# N32H488 register map
Vendor: Nationstech Ltd.; File version: 1.0
Registers are 32-bit, read-write, reset 0x0 unless marked. A register's access mark holds for its fields unless they carry their own. Offsets are from the block's base; [hi:lo] are bit positions; {n}, {i} and the like mark numbered series; 'fields as' and 'values as' point back to an identical list.

## SHRTIM_Master — Super high resolution timer: Master Timers
Base 0x40030000
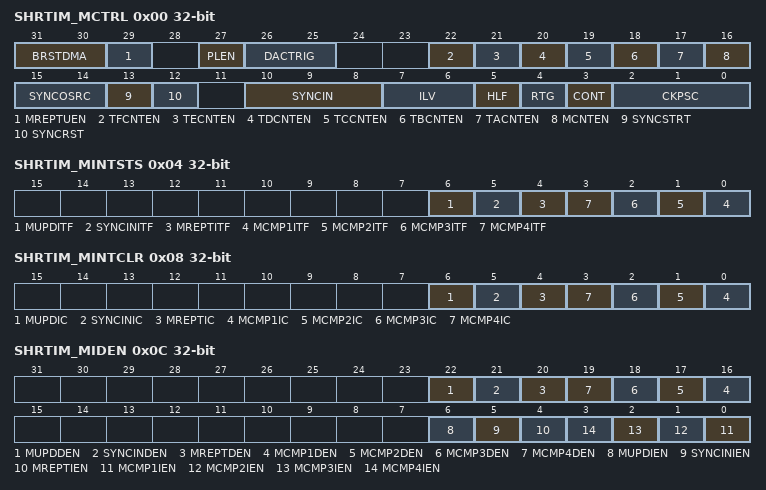
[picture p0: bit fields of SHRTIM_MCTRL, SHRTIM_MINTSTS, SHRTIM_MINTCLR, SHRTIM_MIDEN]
0x00 SHRTIM_MCTRL — SHRTIM configuration register for master timer
  [31:30] BRSTDMA, [29] MREPTUEN, [27] PLEN, [26:25] DACTRIG, [22] TFCNTEN, [21] TECNTEN, [20] TDCNTEN, [19] TCCNTEN, [18] TBCNTEN, [17] TACNTEN, [16] MCNTEN, [15:14] SYNCOSRC, [13] SYNCSTRT, [12] SYNCRST, [10:8] SYNCIN, [7:6] ILV, [5] HLF, [4] RTG, [3] CONT, [2:0] CKPSC
0x04 SHRTIM_MINTSTS ro — SHRTIM status register for master timer interrupt
  [6] MUPDITF, [5] SYNCINITF, [4] MREPTITF, [n-1] MCMP{n}ITF (n=1..4)
0x08 SHRTIM_MINTCLR wo — SHRTIM master timer interrupt clear register
  [6] MUPDIC, [5] SYNCINIC, [4] MREPTIC, [n-1] MCMP{n}IC (n=1..4)
0x0C SHRTIM_MIDEN — SHRTIM master timer interrupt and DMA request enable register
  [22] MUPDDEN, [21] SYNCINDEN, [20] MREPTDEN, [n+15] MCMP{n}DEN (n=1..4), [6] MUPDIEN, [5] SYNCINIEN, [4] MREPTIEN, [n-1] MCMP{n}IEN (n=1..4)
0x10 SHRTIM_MCNT — SHRTIM master timer counter register
  [15:0] MCOUNT
0x14 SHRTIM_MPRD reset 0xFFDF — SHRTIM master timer period register
  [15:0] MPRD
0x18 SHRTIM_MREPT — SHRTIM master timer repetition register
  [7:0] MREPT
0x1C SHRTIM_MCMP1DAT — SHRTIM master timer compare 1 register
  [15:0] MCMP1DAT
{0x1C+4i} SHRTIM_MCMP{i}DAT (i=2..4) — SHRTIM master timer compare {i} register
  [15:0] MCMP{i}DAT
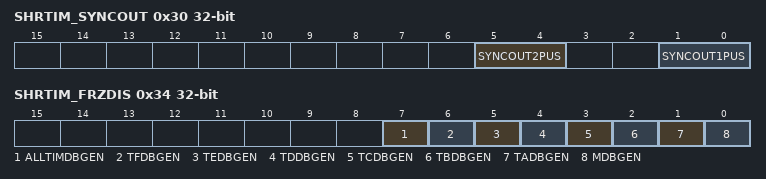
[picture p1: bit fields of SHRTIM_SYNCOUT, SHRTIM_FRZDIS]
0x30 SHRTIM_SYNCOUT — SYNOUT configure register
  [5:4] SYNCOUT2PUS, [1:0] SYNCOUT1PUS
0x34 SHRTIM_FRZDIS — Timer behavior during CPU freeze
  [7] ALLTIMDBGEN, [6] TFDBGEN, [5] TEDBGEN, [4] TDDBGEN, [3] TCDBGEN, [2] TBDBGEN, [1] TADBGEN, [0] MDBGEN

## USB_FS — Universal serial bus full-speed device interface
Base 0x40004800
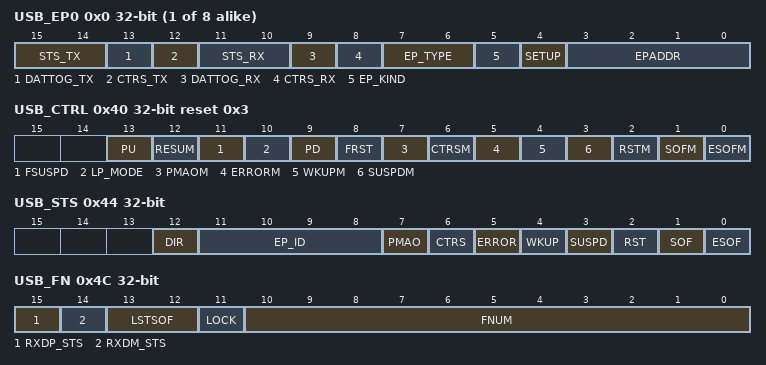
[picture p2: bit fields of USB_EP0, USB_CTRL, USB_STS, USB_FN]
{0x0+4i} USB_EP{i} (i=0..7)
  [15:14] STS_TX, [13] DATTOG_TX, [12] CTRS_TX, [11:10] STS_RX, [9] DATTOG_RX, [8] CTRS_RX, [7:6] EP_TYPE, [5] EP_KIND, [4] SETUP, [3:0] EPADDR
0x40 USB_CTRL reset 0x3 (reset mask 0xFF1F)
  [13] PU, [12] RESUM, [11] FSUSPD, [10] LP_MODE, [9] PD, [8] FRST, [7] PMAOM, [6] CTRSM, [5] ERRORM, [4] WKUPM, [3] SUSPDM, [2] RSTM, [1] SOFM, [0] ESOFM
0x44 USB_STS (reset mask 0xFF1F)
  [12] DIR, [11:8] EP_ID, [7] PMAO, [6] CTRS, [5] ERROR, [4] WKUP, [3] SUSPD, [2] RST, [1] SOF, [0] ESOF
0x48 USB_BUFTAB
  [15:3] BUFTAB
0x4C USB_FN
  [15] RXDP_STS, [14] RXDM_STS, [13:12] LSTSOF, [11] LOCK, [10:0] FNUM
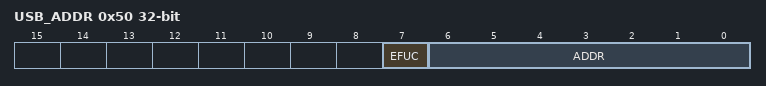
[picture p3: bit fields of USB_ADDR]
0x50 USB_ADDR (reset mask 0x7F)
  [7] EFUC, [6:0] ADDR

## USB_HS — USB high speed dual role
Base 0x40040000
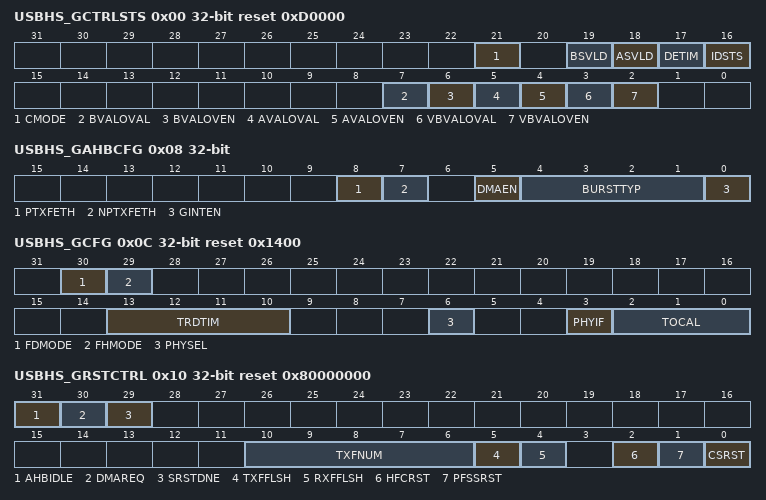
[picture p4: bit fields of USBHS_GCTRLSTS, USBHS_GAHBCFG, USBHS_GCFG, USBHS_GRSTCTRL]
0x00 USBHS_GCTRLSTS reset 0xD0000 — USBHS global control and status register
  [21] CMODE ro, [19] BSVLD ro, [18] ASVLD ro, [17] DETIM ro, [16] IDSTS ro, [7] BVALOVAL, [6] BVALOVEN, [5] AVALOVAL, [4] AVALOVEN, [3] VBVALOVAL, [2] VBVALOVEN
0x08 USBHS_GAHBCFG
  [8] PTXFETH, [7] NPTXFETH, [5] DMAEN, [4:1] BURSTTYP, [0] GINTEN
0x0C USBHS_GCFG reset 0x1400
  [30] FDMODE, [29] FHMODE, [13:10] TRDTIM, [6] PHYSEL, [3] PHYIF wo, [2:0] TOCAL
0x10 USBHS_GRSTCTRL reset 0x80000000
  [31] AHBIDLE ro, [30] DMAREQ ro, [29] SRSTDNE ro, [10:6] TXFNUM, [5] TXFFLSH, [4] RXFFLSH, [2] HFCRST, [1] PFSSRST, [0] CSRST
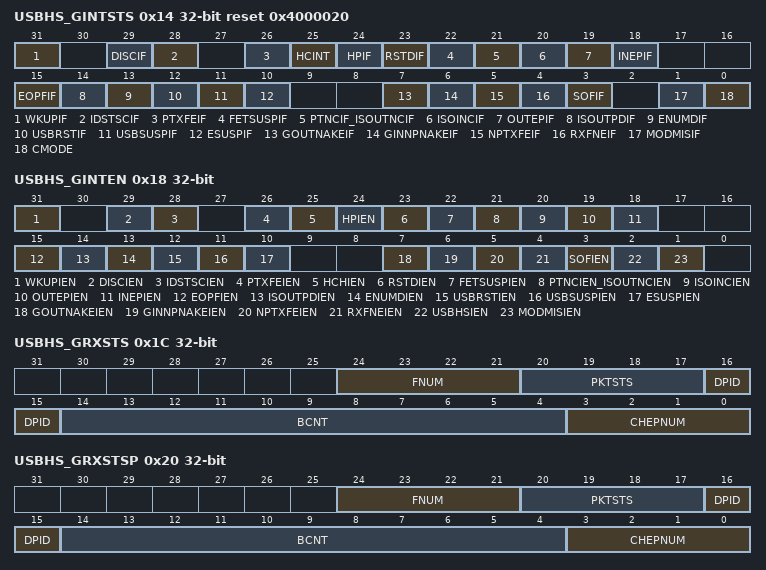
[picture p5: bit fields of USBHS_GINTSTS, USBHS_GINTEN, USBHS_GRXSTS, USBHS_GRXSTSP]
0x14 USBHS_GINTSTS reset 0x4000020
  [31] WKUPIF
  [29] DISCIF
  [28] IDSTSCIF
  [26] PTXFEIF ro
  [25] HCINT ro — Host channels interrupt
  [24] HPIF ro
  [23] RSTDIF
  [22] FETSUSPIF
  [21] PTNCIF_ISOUTNCIF
  [20] ISOINCIF
  [19] OUTEPIF ro
  [18] INEPIF ro
  [15] EOPFIF
  [14] ISOUTPDIF
  [13] ENUMDIF
  [12] USBRSTIF
  [11] USBSUSPIF
  [10] ESUSPIF
  [7] GOUTNAKEIF ro
  [6] GINNPNAKEIF ro
  [5] NPTXFEIF ro
  [4] RXFNEIF ro
  [3] SOFIF
  [1] MODMISIF
  [0] CMODE ro
0x18 USBHS_GINTEN
  [31] WKUPIEN, [29] DISCIEN, [28] IDSTSCIEN, [26] PTXFEIEN, [25] HCHIEN, [24] HPIEN, [23] RSTDIEN, [22] FETSUSPIEN, [21] PTNCIEN_ISOUTNCIEN, [20] ISOINCIEN, [19] OUTEPIEN, [18] INEPIEN, [15] EOPFIEN, [14] ISOUTPDIEN, [13] ENUMDIEN, [12] USBRSTIEN, [11] USBSUSPIEN, [10] ESUSPIEN, [7] GOUTNAKEIEN, [6] GINNPNAKEIEN, [5] NPTXFEIEN, [4] RXFNEIEN, [3] SOFIEN, [2] USBHSIEN, [1] MODMISIEN
0x1C USBHS_GRXSTS ro
  [24:21] FNUM, [20:17] PKTSTS, [16:15] DPID, [14:4] BCNT, [3:0] CHEPNUM
0x20 USBHS_GRXSTSP ro
  fields as USBHS_GRXSTS
0x24 USBHS_GRXFSIZ reset 0x200
  [10:0] RXFDEP
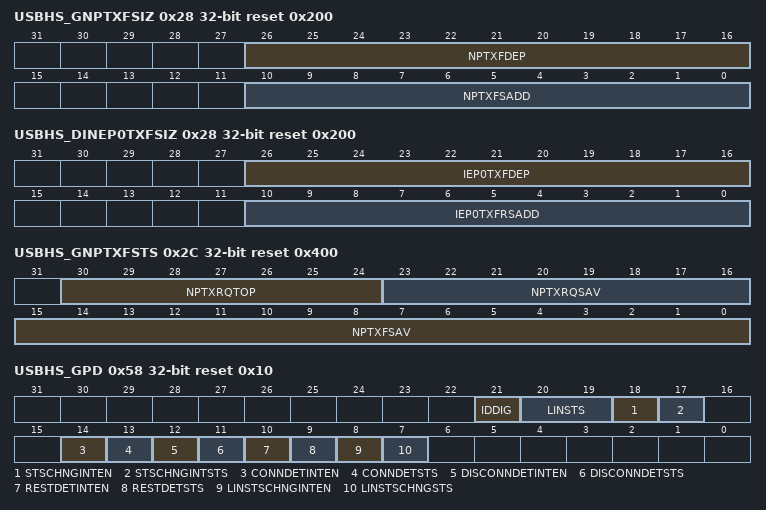
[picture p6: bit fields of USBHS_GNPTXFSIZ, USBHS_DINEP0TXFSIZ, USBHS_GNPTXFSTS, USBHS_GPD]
0x28 USBHS_GNPTXFSIZ reset 0x200
  [26:16] NPTXFDEP
  [10:0] NPTXFSADD — NNPTXFSADD
0x28 USBHS_DINEP0TXFSIZ reset 0x200 (alternate view of USBHS_GNPTXFSIZ) — EUSBHS_DINEP0TXFSIZ
  [26:16] IEP0TXFDEP, [10:0] IEP0TXFRSADD
0x2C USBHS_GNPTXFSTS ro reset 0x400
  [30:24] NPTXRQTOP, [23:16] NPTXRQSAV, [15:0] NPTXFSAV
0x3C USBHS_CID reset 0x3608
0x58 USBHS_GPD reset 0x10
  [21] IDDIG, [20:19] LINSTS, [18] STSCHNGINTEN, [17] STSCHNGINTSTS, [14] CONNDETINTEN, [13] CONNDETSTS, [12] DISCONNDETINTEN, [11] DISCONNDETSTS, [10] RESTDETINTEN, [9] RESTDETSTS, [8] LINSTSCHNGINTEN, [7] LINSTSCHNGSTS
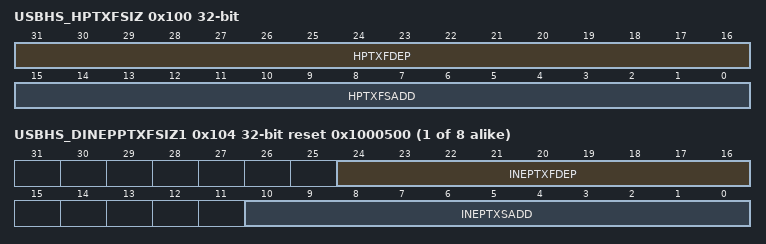
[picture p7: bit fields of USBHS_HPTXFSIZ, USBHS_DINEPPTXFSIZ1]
0x100 USBHS_HPTXFSIZ
  [31:16] HPTXFDEP, [15:0] HPTXFSADD
{0x100+4i} USBHS_DINEPPTXFSIZ{i} reset 0x1000500 (i=1..8)
  [24:16] INEPTXFDEP, [10:0] INEPTXSADD
